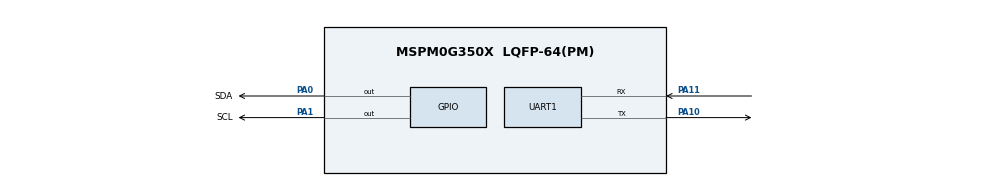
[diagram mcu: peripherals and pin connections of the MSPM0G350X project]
/**
 * @cliArgs --device "MSPM0G350X" --part "Default" --package "LQFP-64(PM)" --product "mspm0_sdk@2.10.00.04"
 * @versions {"tool":"1.27.0+4565"}
 */

/**
 * Import the modules used in this configuration.
 */
const GPIO   = scripting.addModule("/ti/driverlib/GPIO", {}, false);
const GPIO1  = GPIO.addInstance();
const SYSCTL = scripting.addModule("/ti/driverlib/SYSCTL");
const UART   = scripting.addModule("/ti/driverlib/UART", {}, false);
const UART1  = UART.addInstance();

/**
 * Write custom configuration values to the imported modules.
 */
const gate7  = system.clockTree["MFCLKGATE"];
gate7.enable = true;

GPIO1.$name                          = "IIC_Software";
GPIO1.port                           = "PORTA";
GPIO1.associatedPins.create(2);
GPIO1.associatedPins[0].$name        = "SDA";
GPIO1.associatedPins[0].initialValue = "SET";
GPIO1.associatedPins[0].ioStructure  = "OD";
GPIO1.associatedPins[0].pin.$assign  = "PA0";
GPIO1.associatedPins[1].$name        = "SCL";
GPIO1.associatedPins[1].initialValue = "SET";
GPIO1.associatedPins[1].ioStructure  = "OD";
GPIO1.associatedPins[1].assignedPin  = "1";
GPIO1.associatedPins[1].pin.$assign  = "PA1";

const Board = scripting.addModule("/ti/driverlib/Board", {}, false);

SYSCTL.forceDefaultClkConfig = true;
SYSCTL.clockTreeEn           = true;

UART1.$name                    = "UART_0";
UART1.enabledInterrupts        = ["RX"];
UART1.peripheral.$assign       = "UART0";
UART1.peripheral.rxPin.$assign = "PA11";
UART1.peripheral.txPin.$assign = "PA10";
UART1.txPinConfig.$name        = "ti_driverlib_gpio_GPIOPinGeneric0";
UART1.rxPinConfig.$name        = "ti_driverlib_gpio_GPIOPinGeneric1";

/**
 * Pinmux solution for unlocked pins/peripherals. This ensures that minor changes to the automatic solver in a future
 * version of the tool will not impact the pinmux you originally saw.  These lines can be completely deleted in order to
 * re-solve from scratch.
 */
Board.peripheral.$suggestSolution          = "DEBUGSS";
Board.peripheral.swclkPin.$suggestSolution = "PA20";
Board.peripheral.swdioPin.$suggestSolution = "PA19";
